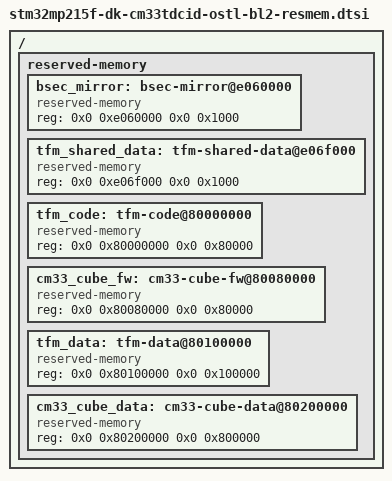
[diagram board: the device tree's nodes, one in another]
// SPDX-License-Identifier: (GPL-2.0-only OR BSD-3-Clause)
/*
 * Copyright (C) STMicroelectronics 2024 - All Rights Reserved
 * Author: Loic Pallardy loic.pallardy@foss.st.com for STMicroelectronics.
 */

/*
 * stm32mp215f reserved memory device tree configuration
 * Project : ostl
 * Generated by XLmx tool version 2.8 - 3/3/2025 9:57:26 AM
 */

/ {
	reserved-memory {
		#address-cells = <2>;
		#size-cells = <2>;
		ranges;

		/* Internal RAM reserved memory declaration */
		bsec_mirror: bsec-mirror@e060000 {
			compatible = "reserved-memory";
			reg = <0x0 0xe060000 0x0 0x1000>;
			#memory-region-cells = <0>;
		};

		tfm_shared_data: tfm-shared-data@e06f000 {
			compatible = "reserved-memory";
			reg = <0x0 0xe06f000 0x0 0x1000>;
			#memory-region-cells = <0>;
		};

		/* Octo Memory Manager reserved memory declaration */
		/* DDR reserved memory declaration */
		tfm_code: tfm-code@80000000 {
			compatible = "reserved-memory";
			reg = <0x0 0x80000000 0x0 0x80000>;
			#memory-region-cells = <0>;
		};

		cm33_cube_fw: cm33-cube-fw@80080000 {
			compatible = "reserved-memory";
			reg = <0x0 0x80080000 0x0 0x80000>;
			#memory-region-cells = <0>;
		};

		tfm_data: tfm-data@80100000 {
			compatible = "reserved-memory";
			reg = <0x0 0x80100000 0x0 0x100000>;
			#memory-region-cells = <0>;
		};

		cm33_cube_data: cm33-cube-data@80200000 {
			compatible = "reserved-memory";
			reg = <0x0 0x80200000 0x0 0x800000>;
			#memory-region-cells = <0>;
		};
	};
};
